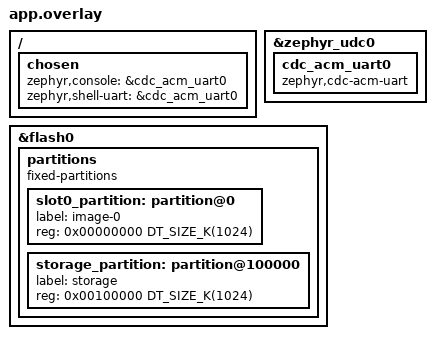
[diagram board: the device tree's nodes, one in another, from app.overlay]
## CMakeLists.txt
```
cmake_minimum_required(VERSION 3.20)

find_package(Zephyr REQUIRED HINTS $ENV{ZEPHYR_BASE})

project(stm32_lua_system)

# Ensure lparser.c is here!
set(LUA_SOURCES
    lua/lapi.c lua/lcode.c lua/lctype.c lua/ldebug.c lua/ldo.c 
    lua/ldump.c lua/lfunc.c lua/lgc.c lua/llex.c lua/lmem.c 
    lua/lobject.c lua/lopcodes.c lua/lstate.c lua/lstring.c 
    lua/ltable.c lua/ltm.c lua/lundump.c lua/lvm.c lua/lzio.c
    lua/lauxlib.c lua/lbaselib.c lua/lcorolib.c lua/ldblib.c 
    lua/liolib.c lua/lmathlib.c lua/loadlib.c lua/loslib.c 
    lua/lstrlib.c lua/ltablib.c lua/lutf8lib.c lua/linit.c
    lua/lparser.c
)

target_sources(app PRIVATE src/main.c ${LUA_SOURCES})
target_include_directories(app PRIVATE lua)

# THE FIX: Tell the linker to allow multiple definitions of symbols like 'remove'
target_link_options(app PUBLIC "-Wl,--allow-multiple-definition")

# Link math library
target_link_libraries(app PUBLIC -lm)
```

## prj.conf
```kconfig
# Basic OS Config
CONFIG_NEWLIB_LIBC=y
CONFIG_MAIN_STACK_SIZE=8192
CONFIG_HEAP_MEM_POOL_SIZE=256000

# FPU Support (Crucial for math.pi)
CONFIG_FPU=y
CONFIG_FPU_SHARING=y

# Networking
CONFIG_NETWORKING=y
CONFIG_NET_L2_ETHERNET=y
CONFIG_NET_IPV4=y
CONFIG_NET_TCP=y
CONFIG_NET_DHCPV4=y

# USB & Shell
CONFIG_USB_DEVICE_STACK=y
CONFIG_USB_DEVICE_PRODUCT="STM32 Lua Node"
CONFIG_SERIAL=y
CONFIG_UART_LINE_CTRL=y
CONFIG_SHELL=y
CONFIG_SHELL_BACKEND_SERIAL=y
CONFIG_UART_CONSOLE=y

# Increase Shell Stack for Lua
CONFIG_SHELL_STACK_SIZE=4096

# File System
CONFIG_FLASH=y
CONFIG_FLASH_MAP=y
CONFIG_FILE_SYSTEM=y
CONFIG_FILE_SYSTEM_LITTLEFS=y
CONFIG_FILE_SYSTEM_MKFS=y
CONFIG_FILE_SYSTEM_SHELL=y

# Force LittleFS to respect the STM32H7 32-byte flash alignment
CONFIG_FS_LITTLEFS_READ_SIZE=32
CONFIG_FS_LITTLEFS_PROG_SIZE=32
CONFIG_FS_LITTLEFS_CACHE_SIZE=128
CONFIG_FS_LITTLEFS_LOOKAHEAD_SIZE=32

# Debugging Faults
CONFIG_HW_STACK_PROTECTION=y

# Shell and network and features we want
CONFIG_NET_SHELL=y
CONFIG_NET_DHCPV4=y
CONFIG_NET_CONFIG_SETTINGS=y
CONFIG_NET_CONFIG_NEED_IPV4=y
CONFIG_NET_STATISTICS=y
CONFIG_HTTP_SERVER=y
CONFIG_DNS_RESOLVER=y
CONFIG_NET_DHCPV4_LOG_LEVEL_INF=y

# Modern Zephyr POSIX flags for clock_settime()
CONFIG_POSIX_API=y
CONFIG_POSIX_TIMERS=y

# Enable the Hardware PTP Clock subsystem
CONFIG_PTP_CLOCK=y
CONFIG_NET_L2_PTP=y

# Enable the gPTP Protocol Stack
CONFIG_NET_GPTP=y

# (Optional but recommended) Increase buffers
# gPTP sends frequent multicast packets; giving the network stack 
# a bit more breathing room prevents packet drops.
CONFIG_NET_BUF_RX_COUNT=32
CONFIG_NET_BUF_TX_COUNT=32
```

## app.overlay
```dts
/ {
    chosen {
        zephyr,console = &cdc_acm_uart0;
        zephyr,shell-uart = &cdc_acm_uart0;
    };
};

&zephyr_udc0 {
    cdc_acm_uart0: cdc_acm_uart0 {
        compatible = "zephyr,cdc-acm-uart";
    };
};

/* Target the flash controller's partition list directly */
&flash0 {
    /delete-node/ partitions;

    partitions {
        compatible = "fixed-partitions";
        #address-cells = <1>;
        #size-cells = <1>;

        /* 1MB for the Application */
        slot0_partition: partition@0 {
            label = "image-0";
            reg = <0x00000000 DT_SIZE_K(1024)>;
        };

        /* 1MB for LittleFS */
        storage_partition: partition@100000 {
            label = "storage";
            reg = <0x00100000 DT_SIZE_K(1024)>;
        };
    };
};
```

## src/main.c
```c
#include <zephyr/kernel.h>
#include <zephyr/device.h>
#include <zephyr/drivers/uart.h>
#include <zephyr/usb/usb_device.h>
#include <zephyr/fs/fs.h>
#include <zephyr/storage/flash_map.h>
#include <zephyr/logging/log.h>

#include <zephyr/net/socket.h>
#include <zephyr/fs/fs.h>
#include <time.h>
#include <zephyr/net/ethernet.h>
#include <zephyr/drivers/ptp_clock.h>

/* Lua Includes */
#include <lua.h>
#include <lualib.h>
#include <lauxlib.h>

LOG_MODULE_REGISTER(main);

/* 1. File System Setup (LittleFS) */
#include <zephyr/fs/littlefs.h>
FS_LITTLEFS_DECLARE_DEFAULT_CONFIG(storage);
static struct fs_mount_t lfs_storage_mount = {
    .type = FS_LITTLEFS,
    .fs_data = &storage,
    .storage_dev = (void *)FIXED_PARTITION_ID(storage_partition),
    .mnt_point = "/lfs",
};

/* 2. Lua Custom Print (Redirects to Zephyr Console) */
static int l_zephyr_print(lua_State *L) {
    int n = lua_gettop(L);
    for (int i = 1; i <= n; i++) {
        size_t len;
        const char *s = luaL_tolstring(L, i, &len);
        if (i > 1) printk("\t");
        printk("%s", s);
        lua_pop(L, 1);
    }
    printk("\n");
    return 0;
}

/* 3. Helper to Run Lua Strings */
void run_lua(lua_State *L, const char *code) {
    if (luaL_dostring(L, code) != LUA_OK) {
        printk("Error: %s\n", lua_tostring(L, -1));
        lua_pop(L, 1);
    }
}

#include <zephyr/shell/shell.h>

static lua_State *L = NULL;

// This allows you to type: lua "print(10 + 20)" in the terminal
static int cmd_lua(const struct shell *sh, size_t argc, char **argv)
{
    if (L == NULL) {
        shell_error(sh, "Lua VM not initialized");
        return -ENOENT;
    }
    
    if (argc < 2) {
        shell_error(sh, "Usage: lua \"<code>\"");
        return -EINVAL;
    }

    // Execute the string passed from the terminal
    if (luaL_dostring(L, argv[1]) != LUA_OK) {
        shell_error(sh, "Lua Error: %s", lua_tostring(L, -1));
        lua_pop(L, 1); // Clean up the error message from stack
    }
    return 0;
}


SHELL_CMD_REGISTER(lua, NULL, "Run a Lua string", cmd_lua);


/* Background thread to sync the hardware PTP clock to the OS clock */
void ptp_to_sys_thread(void) {
    /* Wait a few seconds on boot to let gPTP negotiate */
    k_sleep(K_SECONDS(5)); 

    struct net_if *iface = net_if_get_default();
    const struct device *ptp_dev = net_eth_get_ptp_clock(iface);
    
    if (!ptp_dev) {
        printk("Failed to find PTP device for clock sync.\n");
        return;
    }

    while (1) {
        struct net_ptp_time ptp_time;
        /* Read the hardware MAC */
        if (ptp_clock_get(ptp_dev, &ptp_time) == 0) {
            
            /* Format it for the OS */
            struct timespec ts;
            ts.tv_sec = ptp_time.second;
            ts.tv_nsec = ptp_time.nanosecond;
            
            /* Overwrite the Zephyr system time */
            clock_settime(CLOCK_REALTIME, &ts);
        }
        
        /* Go to sleep for 1 second, then do it again */
        k_sleep(K_SECONDS(1)); 
    }
}
/* Tell Zephyr to run this continuously in the background */
K_THREAD_DEFINE(ptp_sys_sync_tid, 1024, ptp_to_sys_thread, NULL, NULL, NULL, 7, 0, 0);


static int luaPanic(lua_State *L) {
    const char *msg = lua_tostring(L, -1);
    printk("!!! LUA PANIC !!! : %s\n", msg ? msg : "unknown error");
    return 0; // Return to hang or reset
}


/* --- 1. The Network Upload Thread --- */
void tcp_upload_thread(void) {
    int serv = zsock_socket(AF_INET, SOCK_STREAM, IPPROTO_TCP);
    struct sockaddr_in bind_addr = {
        .sin_family = AF_INET,
        .sin_port = htons(1234),
        .sin_addr.s_addr = htonl(INADDR_ANY),
    };
    
    zsock_bind(serv, (struct sockaddr *)&bind_addr, sizeof(bind_addr));
    zsock_listen(serv, 1);

    while (1) {
        /* Wait for a connection from your Ubuntu machine */
        int client = zsock_accept(serv, NULL, NULL);
        if (client < 0) continue;

        printk("\n[NET] Incoming Lua script detected...\n");
        
        struct fs_file_t file;
        fs_file_t_init(&file);
	fs_unlink("/lfs/main.lua");
	fs_open(&file, "/lfs/main.lua", FS_O_CREATE | FS_O_WRITE);
        fs_truncate(&file, 0); /* Clear the old file */

        char buf[256];
        int len;
	int total_rx = 0;
        int total_wr = 0;

        /* Receive data in chunks */
        while ((len = zsock_recv(client, buf, sizeof(buf), 0)) > 0) {
            total_rx += len;
            int wlen = fs_write(&file, buf, len);
	    printk("[upload] writing %d returned %d\n", len, wlen);
            if (wlen > 0) {
                total_wr += wlen;
            } else {
                printk("[FS] fs_write failed with error: %d\n", wlen);
            }
        }
        
        if (len < 0) {
            printk("[NET] Socket error during receive: %d\n", len);
        }

	int closeSts = fs_close(&file);
	printk("[upload] fs_close returns %d\n", closeSts);

        zsock_close(client);
	printk("[upload] Received: %d bytes | Wrote: %d bytes\n",
	       total_rx, total_wr);
    }
}
/* Tell Zephyr to run this function constantly in the background */
K_THREAD_DEFINE(upload_tid, 4096, tcp_upload_thread, NULL, NULL, NULL, 7, 0, 0);


/* --- 2. The Command to RUN the saved file --- */
static int cmd_luarun(const struct shell *sh, size_t argc, char **argv) {
    char *nameP = (argc >= 2) ? argv[1] : "/lfs/main.lua";
    printk("[luarun] running '%s'\n", nameP);

    struct fs_file_t file;
    fs_file_t_init(&file);
    if (fs_open(&file, nameP, FS_O_READ) < 0) {
        shell_error(sh, "Could not open %s", nameP);
        return -ENOENT;
    }
    
    /* Get file size */
    struct fs_dirent entry;
    fs_stat(nameP, &entry);
    size_t size = entry.size;
    
    /* Read the whole file into RAM (STM32H7 has plenty!) */
    char *script_buf = k_malloc(size + 1);
    fs_read(&file, script_buf, size);
    script_buf[size] = '\0'; /* Null-terminate the string */
    fs_close(&file);
    
    /* Execute it in our global Lua State (L) */
    if (luaL_dostring(L, script_buf) != LUA_OK) {
        shell_error(sh, "Lua Error: %s", lua_tostring(L, -1));
        lua_pop(L, 1);
    }
    
    k_free(script_buf);
    return 0;
}
SHELL_CMD_REGISTER(luarun, NULL, "Run a script: luarun /lfs/main.lua", cmd_luarun);


// Stubs
int _link() {return -1;}
int _unlink() {return -1;}
int _times() {return -1;}

int main(void) {
    int ret;

    /* A. Initialize USB CDC ACM for the Console */
    const struct device *dev = DEVICE_DT_GET(DT_CHOSEN(zephyr_console));
    if (usb_enable(NULL)) {
        return 0;
    }

    /* Wait for DTR (optional: waits for you to open a terminal) */
    uint32_t dtr = 0;
    while (!dtr) {
        uart_line_ctrl_get(dev, UART_LINE_CTRL_DTR, &dtr);
        k_msleep(100);
    }

    /* --- Mount File System --- */
    int fs_res = fs_mount(&lfs_storage_mount);
    if (fs_res != 0) {
        printk("LittleFS mount failed (%d). Formatting...\n", fs_res);
        
        /* Format the partition */
        fs_res = fs_mkfs(FS_LITTLEFS, (uintptr_t)FIXED_PARTITION_ID(storage_partition), &storage, 0);
        if (fs_res == 0) {
            printk("Format successful. Mounting...\n");
            fs_res = fs_mount(&lfs_storage_mount);
        } else {
            printk("Format failed with error %d\n", fs_res);
        }
    }
    
    if (fs_res == 0) {
        printk("LittleFS mounted successfully at /lfs\n");
    }    

    /* C. Initialize Lua State */
    L = luaL_newstate();
    lua_atpanic(L, luaPanic);
    luaL_openlibs(L);
    lua_register(L, "print", l_zephyr_print);

    printk("--- Lua 5.4 Virtual Machine Ready ---\n");

    /* D. Execute a Test Script */
    run_lua(L, "print('Hardware: STM32H753ZI')");
    run_lua(L, "print('Memory Test: ', 2^20 / 1024, 'KB')");

    /* Main loop - usually you'd launch a Shell or HTTP thread here */
    while (1) {
        k_sleep(K_FOREVER);
    }

    lua_close(L);
    return 0;
}
```
